VERSION "HIPBNYYYYYYYYYYYYYYYYYYYYYYYYYYYNNNYNNNNNN/4/%%%/4/'%**4NNN///"

NS_ :

BS_:

BU_: ReceiveNode TransmitNode

BO_ 1536 DiagResponse: 8 Vector__XXX

BO_ 1792 DiagRequest: 8 Vector__XXX

BO_ 2 Ant_LockingRemoteControlRequest: 1 TransmitNode
 SG_ Ant_LockRequest : 0|8@1- (1,0) [0|0] "" Vector__XXX

BO_ 1 Ant_VehicleMotion: 2 TransmitNode
 SG_ Ant_EngineRunning : 8|5@1- (1,0) [0|0] "" Vector__XXX
 SG_ Ant_CrashDetected : 0|6@1- (1,0) [0|0] "" Vector__XXX

BO_ 68 Ant_WindowControl: 2 TransmitNode
 SG_ Ant_KeyDown : 8|6@1- (1,0) [0|0] "" Vector__XXX
 SG_ Ant_KeyUp : 0|6@1- (1,0) [0|0] "" Vector__XXX

BO_ 17 Ant_WindowState: 2 ReceiveNode
 SG_ Ant_windowPosition : 8|8@1- (1,0) [0|0] "" Vector__XXX
 SG_ Ant_WindowMotion : 0|4@1- (1,0) [0|0] "" Vector__XXX

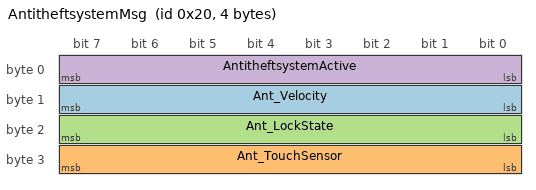
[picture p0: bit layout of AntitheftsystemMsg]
BO_ 32 AntitheftsystemMsg: 4 TransmitNode
 SG_ Ant_Velocity : 8|8@1- (1,0) [0|0] "" Vector__XXX
 SG_ Ant_TouchSensor : 24|8@1- (1,0) [0|0] "" Vector__XXX
 SG_ Ant_LockState : 16|8@1+ (1,0) [0|1] "" Vector__XXX
 SG_ AntitheftsystemActive : 0|8@1+ (1,0) [0|1] "" Vector__XXX

BO_TX_BU_ 1 : ReceiveNode,TransmitNode;
BO_TX_BU_ 68 : ReceiveNode,TransmitNode;
BO_TX_BU_ 17 : ReceiveNode,TransmitNode;
BO_TX_BU_ 32 : ReceiveNode,TransmitNode;

EV_ ENV_MSG1: 0 [0|1] "" 0 1 DUMMY_NODE_VECTOR0 Vector__XXX;

CM_ "CAN communication matrix for body electronics
*******************************************************

implemented: turn lights, warning lights, windows


";
BA_DEF_  "BusType" STRING ;
BA_DEF_ BU_  "TpAddressingMode" INT 0 3;
BA_DEF_ BO_  "GenMsgILSupport" ENUM  "No","Yes";
BA_DEF_ BO_  "GenMsgCycleTimeFast" INT 2 100000;
BA_DEF_ BU_  "ILUsed" ENUM  "Yes","No";
BA_DEF_  "GenNWMSleepTime" INT 0 1000000;
BA_DEF_  "GenEnvVarEndingDsp" STRING ;
BA_DEF_  "GenEnvVarEndingSnd" STRING ;
BA_DEF_  "GenEnvVarPrefix" STRING ;
BA_DEF_ BU_  "NodeLayerModules" STRING ;
BA_DEF_  "NmBaseAddress" HEX 1024 1055;
BA_DEF_ BU_  "NmStationAddress" INT 0 63;
BA_DEF_ BU_  "NmNode" ENUM  "no","yes";
BA_DEF_ BU_  "TpTxIdentifier" HEX 0 536870911;
BA_DEF_ BU_  "TpRxIdentifier" HEX 0 536870911;
BA_DEF_ BU_  "Diagnose-Stationsadresse" HEX 0 255;
BA_DEF_ BU_  "TpRxMask" HEX 0 65535;
BA_DEF_ BU_  "TpCanBus" INT 1 2;
BA_DEF_ BU_  "TpUseFC" INT 0 1;
BA_DEF_ BU_  "TpNodeBaseAddress" HEX 0 33554431;
BA_DEF_ BO_  "GenMsgSendType" ENUM  "Cyclic","not_used","not_used","not_used","not_used","Cyclic","not_used","IfActive";
BA_DEF_ SG_  "GenSigSendType" ENUM  "Cyclic","OnWrite","OnWriteWithRepetition","OnChange","OnChangeWithRepetition","IfActive","IfActiveWithRepetition";
BA_DEF_ BO_  "GenMsgCycleTime" INT 2 50000;
BA_DEF_ BO_  "GenMsgDelayTime" INT 1 1000;
BA_DEF_ BO_  "GenMsgAutoGenSnd" ENUM  "No","Yes";
BA_DEF_ BU_  "GenNodSleepTime" INT 0 1000000;
BA_DEF_ BU_  "GenNodAutoGenSnd" ENUM  "No","Yes";
BA_DEF_ BU_  "GenNodAutoGenDsp" ENUM  "No","Yes";
BA_DEF_ BO_  "GenMsgAutoGenDsp" ENUM  "No","Yes";
BA_DEF_ SG_  "GenSigEnvVarType" ENUM  "int","float","undef";
BA_DEF_DEF_  "BusType" "";
BA_DEF_DEF_  "TpAddressingMode" 1;
BA_DEF_DEF_  "GenMsgILSupport" "Yes";
BA_DEF_DEF_  "GenMsgCycleTimeFast" 100;
BA_DEF_DEF_  "ILUsed" "Yes";
BA_DEF_DEF_  "GenNWMSleepTime" 0;
BA_DEF_DEF_  "GenEnvVarEndingDsp" "Dsp_";
BA_DEF_DEF_  "GenEnvVarEndingSnd" "_";
BA_DEF_DEF_  "GenEnvVarPrefix" "Env";
BA_DEF_DEF_  "NodeLayerModules" "oseknm01.dll";
BA_DEF_DEF_  "NmBaseAddress" 1024;
BA_DEF_DEF_  "NmStationAddress" 0;
BA_DEF_DEF_  "NmNode" "no";
BA_DEF_DEF_  "TpTxIdentifier" 1;
BA_DEF_DEF_  "TpRxIdentifier" 1;
BA_DEF_DEF_  "Diagnose-Stationsadresse" 0;
BA_DEF_DEF_  "TpRxMask" 255;
BA_DEF_DEF_  "TpCanBus" 1;
BA_DEF_DEF_  "TpUseFC" 1;
BA_DEF_DEF_  "TpNodeBaseAddress" 1536;
BA_DEF_DEF_  "GenMsgSendType" "not_used";
BA_DEF_DEF_  "GenSigSendType" "Cyclic";
BA_DEF_DEF_  "GenMsgCycleTime" 2;
BA_DEF_DEF_  "GenMsgDelayTime" 1;
BA_DEF_DEF_  "GenMsgAutoGenSnd" "";
BA_DEF_DEF_  "GenNodSleepTime" 0;
BA_DEF_DEF_  "GenNodAutoGenSnd" "";
BA_DEF_DEF_  "GenNodAutoGenDsp" "";
BA_DEF_DEF_  "GenMsgAutoGenDsp" "";
BA_DEF_DEF_  "GenSigEnvVarType" "undef";
BA_ "BusType" "CAN";
BA_ "GenNWMSleepTime" 5000;
BA_ "Diagnose-Stationsadresse" BU_ TransmitNode 4;
BA_ "GenNodAutoGenDsp" BU_ TransmitNode 1;
BA_ "GenNodAutoGenSnd" BU_ TransmitNode 1;
BA_ "GenNodSleepTime" BU_ TransmitNode 5000;
BA_ "TpRxIdentifier" BU_ TransmitNode 1541;
BA_ "NmNode" BU_ TransmitNode 1;
BA_ "NodeLayerModules" BU_ TransmitNode "dmoseknm.dll,osek_tp.dll,CANoeILNLVector.dll";
BA_ "TpTxIdentifier" BU_ TransmitNode 1540;
BA_ "NmStationAddress" BU_ TransmitNode 26;
BA_ "GenMsgCycleTime" BO_ 32 100;
BA_ "GenMsgAutoGenSnd" BO_ 32 1;
BA_ "GenMsgAutoGenDsp" BO_ 32 1;
VAL_ 2 Ant_LockRequest 3 "Comfort_lock" 2 "Request_unlock" 1 "Request_lock" 0 "idle" ;
VAL_ 17 Ant_WindowMotion 2 "Currently_opening" 1 "Currently_closing" 0 "Not_Moving" ;
VAL_ 32 Ant_TouchSensor 1 "active" 0 "idle" ;
VAL_ 32 Ant_LockState 1 "Locked" 0 "unlocked" ;
VAL_ 32 AntitheftsystemActive 0 "Idle" 1 "Active" ;
